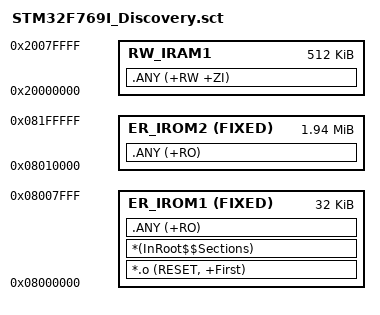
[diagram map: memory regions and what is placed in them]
; *************************************************************
; *** Scatter-Loading Description File generated by uVision ***
; *************************************************************

LR_IROM1 0x08000000 0x00008000  {
  ER_IROM1 0x08000000 FIXED 0x00008000  {
   *.o (RESET, +First)
   *(InRoot$$Sections)
   .ANY (+RO)
  }
}


LR_IROM3 0x08010000 0x001F0000  {
  ER_IROM2 0x08010000 FIXED 0x001F0000  {
   .ANY (+RO)
  }

  RW_IRAM1 0x20000000 0x00080000  {  ; RW data
   .ANY (+RW +ZI)
  }
}
